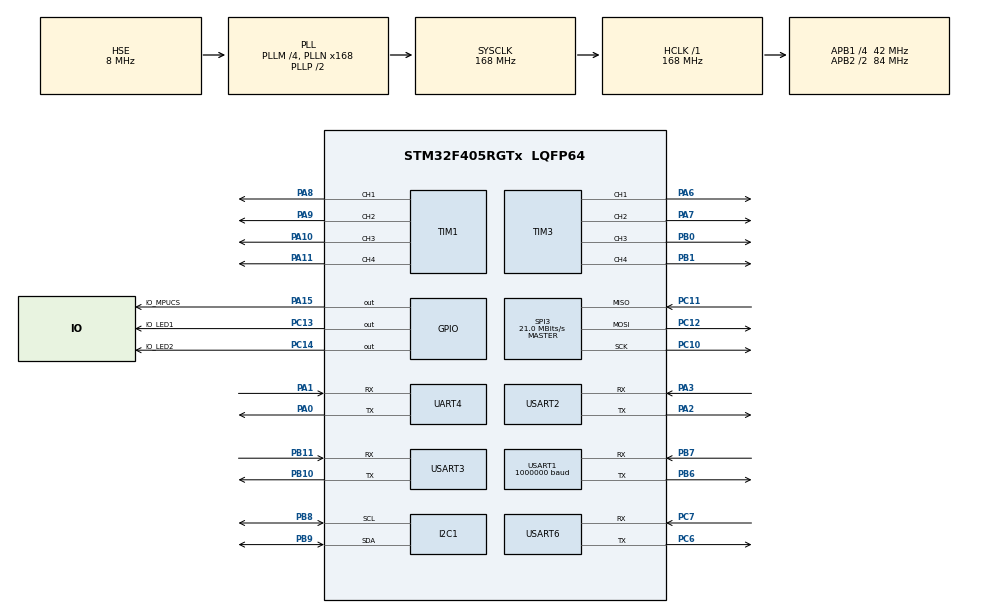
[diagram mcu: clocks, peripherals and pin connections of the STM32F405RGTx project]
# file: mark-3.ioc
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Dma.Request0=USART1_RX
Dma.Request1=USART1_TX
Dma.USART1_RX.0.Direction=DMA_PERIPH_TO_MEMORY
Dma.USART1_RX.0.FIFOMode=DMA_FIFOMODE_ENABLE
Dma.USART1_RX.0.FIFOThreshold=DMA_FIFO_THRESHOLD_FULL
Dma.USART1_RX.0.Instance=DMA2_Stream2
Dma.USART1_RX.0.MemBurst=DMA_MBURST_SINGLE
Dma.USART1_RX.0.MemDataAlignment=DMA_MDATAALIGN_BYTE
Dma.USART1_RX.0.MemInc=DMA_MINC_ENABLE
Dma.USART1_RX.0.Mode=DMA_CIRCULAR
Dma.USART1_RX.0.PeriphBurst=DMA_PBURST_SINGLE
Dma.USART1_RX.0.PeriphDataAlignment=DMA_PDATAALIGN_BYTE
Dma.USART1_RX.0.PeriphInc=DMA_PINC_DISABLE
Dma.USART1_RX.0.Priority=DMA_PRIORITY_LOW
Dma.USART1_TX.1.Direction=DMA_MEMORY_TO_PERIPH
Dma.USART1_TX.1.FIFOMode=DMA_FIFOMODE_ENABLE
Dma.USART1_TX.1.FIFOThreshold=DMA_FIFO_THRESHOLD_FULL
Dma.USART1_TX.1.Instance=DMA2_Stream7
Dma.USART1_TX.1.MemBurst=DMA_MBURST_SINGLE
Dma.USART1_TX.1.MemDataAlignment=DMA_MDATAALIGN_BYTE
Dma.USART1_TX.1.MemInc=DMA_MINC_ENABLE
Dma.USART1_TX.1.Mode=DMA_NORMAL
Dma.USART1_TX.1.PeriphBurst=DMA_PBURST_SINGLE
Dma.USART1_TX.1.PeriphDataAlignment=DMA_PDATAALIGN_BYTE
Dma.USART1_TX.1.PeriphInc=DMA_PINC_DISABLE
Dma.USART1_TX.1.Priority=DMA_PRIORITY_LOW
Mcu.Family=STM32F4
Mcu.Name=STM32F405RGTx
Mcu.Package=LQFP64
NVIC.DMA2_Stream2_IRQn=true\:0\:0\:false\:false\:true\:false\:true\:true
NVIC.DMA2_Stream7_IRQn=true\:0\:0\:false\:false\:true\:false\:true\:true
NVIC.I2C1_EV_IRQn=true\:0\:0\:false\:false\:true\:true\:true\:true
NVIC.PriorityGroup=NVIC_PRIORITYGROUP_4
NVIC.USART1_IRQn=true\:0\:0\:false\:false\:true\:true\:true\:true
PA0-WKUP.Mode=Asynchronous
PA0-WKUP.Signal=UART4_TX
PA1.Mode=Asynchronous
PA1.Signal=UART4_RX
PA10.Signal=S_TIM1_CH3
PA11.Signal=S_TIM1_CH4
PA13.Mode=Trace_Asynchronous_SW
PA13.Signal=SYS_JTMS-SWDIO
PA14.Mode=Trace_Asynchronous_SW
PA14.Signal=SYS_JTCK-SWCLK
PA15.GPIO_Label=IO_MPUCS
PA15.Signal=GPIO_Output
PA2.Mode=Asynchronous
PA2.Signal=USART2_TX
PA3.Mode=Asynchronous
PA3.Signal=USART2_RX
PA6.Signal=S_TIM3_CH1
PA7.Signal=S_TIM3_CH2
PA8.Signal=S_TIM1_CH1
PA9.Signal=S_TIM1_CH2
PB0.Signal=S_TIM3_CH3
PB1.Signal=S_TIM3_CH4
PB10.Mode=Asynchronous
PB10.Signal=USART3_TX
PB11.Mode=Asynchronous
PB11.Signal=USART3_RX
PB3.Mode=Trace_Asynchronous_SW
PB3.Signal=SYS_JTDO-SWO
PB6.Mode=Asynchronous
PB6.Signal=USART1_TX
PB7.Mode=Asynchronous
PB7.Signal=USART1_RX
PB8.Mode=I2C
PB8.Signal=I2C1_SCL
PB9.Mode=I2C
PB9.Signal=I2C1_SDA
PC10.Mode=Full_Duplex_Master
PC10.Signal=SPI3_SCK
PC11.Mode=Full_Duplex_Master
PC11.Signal=SPI3_MISO
PC12.Mode=Full_Duplex_Master
PC12.Signal=SPI3_MOSI
PC13-ANTI_TAMP.GPIO_Label=IO_LED1
PC13-ANTI_TAMP.Signal=GPIO_Output
PC14-OSC32_IN.GPIO_Label=IO_LED2
PC14-OSC32_IN.Signal=GPIO_Output
PC6.Mode=Asynchronous
PC6.Signal=USART6_TX
PC7.Mode=Asynchronous
PC7.Signal=USART6_RX
PH0-OSC_IN.Mode=HSE-External-Oscillator
PH0-OSC_IN.Signal=RCC_OSC_IN
PH1-OSC_OUT.Mode=HSE-External-Oscillator
PH1-OSC_OUT.Signal=RCC_OSC_OUT
ProjectManager.HeapSize=0x200
ProjectManager.StackSize=0x400
ProjectManager.TargetToolchain=STM32CubeIDE
RCC.48MHZClocksFreq_Value=84000000
RCC.AHBFreq_Value=168000000
RCC.APB1CLKDivider=RCC_HCLK_DIV4
RCC.APB1Freq_Value=42000000
RCC.APB1TimFreq_Value=84000000
RCC.APB2CLKDivider=RCC_HCLK_DIV2
RCC.APB2Freq_Value=84000000
RCC.APB2TimFreq_Value=168000000
RCC.CortexFreq_Value=168000000
RCC.HCLKFreq_Value=168000000
RCC.HSE_VALUE=8000000
RCC.HSI_VALUE=16000000
RCC.LSE_VALUE=32768
RCC.PLLM=4
RCC.PLLN=168
RCC.PLLSourceVirtual=RCC_PLLSOURCE_HSE
RCC.SYSCLKFreq_VALUE=168000000
RCC.SYSCLKSource=RCC_SYSCLKSOURCE_PLLCLK
RCC.VCOOutputFreq_Value=336000000
SH.S_TIM1_CH1.0=TIM1_CH1,PWM Generation1 CH1
SH.S_TIM1_CH2.0=TIM1_CH2,PWM Generation2 CH2
SH.S_TIM1_CH3.0=TIM1_CH3,PWM Generation3 CH3
SH.S_TIM1_CH4.0=TIM1_CH4,PWM Generation4 CH4
SH.S_TIM3_CH1.0=TIM3_CH1,PWM Generation1 CH1
SH.S_TIM3_CH2.0=TIM3_CH2,PWM Generation2 CH2
SH.S_TIM3_CH3.0=TIM3_CH3,PWM Generation3 CH3
SH.S_TIM3_CH4.0=TIM3_CH4,PWM Generation4 CH4
SPI3.CalculateBaudRate=21.0 MBits/s
SPI3.Direction=SPI_DIRECTION_2LINES
SPI3.Mode=SPI_MODE_MASTER
SPI3.VirtualType=VM_MASTER
TIM1.Channel-PWM\ Generation1\ CH1=TIM_CHANNEL_1
TIM1.Channel-PWM\ Generation2\ CH2=TIM_CHANNEL_2
TIM1.Channel-PWM\ Generation3\ CH3=TIM_CHANNEL_3
TIM1.Channel-PWM\ Generation4\ CH4=TIM_CHANNEL_4
TIM3.Channel-PWM\ Generation1\ CH1=TIM_CHANNEL_1
TIM3.Channel-PWM\ Generation2\ CH2=TIM_CHANNEL_2
TIM3.Channel-PWM\ Generation3\ CH3=TIM_CHANNEL_3
TIM3.Channel-PWM\ Generation4\ CH4=TIM_CHANNEL_4
UART4.VirtualMode=Asynchronous
USART1.BaudRate=1000000
USART1.VirtualMode=VM_ASYNC
USART2.VirtualMode=VM_ASYNC
USART3.VirtualMode=VM_ASYNC
USART6.VirtualMode=VM_ASYNC
VP_TIM1_VS_ClockSourceINT.Mode=Internal
VP_TIM3_VS_ClockSourceINT.Mode=Internal
board=custom

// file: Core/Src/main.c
/* USER CODE BEGIN Header */
/**
  ******************************************************************************
  * @file           : main.c
  * @brief          : Main program body
  ******************************************************************************
  * @attention
  *
  * Copyright (c) 2025 STMicroelectronics.
  * All rights reserved.
  *
  * This software is licensed under terms that can be found in the LICENSE file
  * in the root directory of this software component.
  * If no LICENSE file comes with this software, it is provided AS-IS.
  *
  ******************************************************************************
  */
/* USER CODE END Header */
#include "main.h"

/* USER CODE BEGIN PM */

#ifdef USE_NON_CUBEIDE_CODE
#include "mark3_main.hpp"
#endif /* USE_NON_CUBEIDE_CODE */

/* USER CODE END PM */

I2C_HandleTypeDef hi2c1;

SPI_HandleTypeDef hspi3;

TIM_HandleTypeDef htim1;
TIM_HandleTypeDef htim3;

UART_HandleTypeDef huart4;
UART_HandleTypeDef huart1;
UART_HandleTypeDef huart2;
UART_HandleTypeDef huart3;
UART_HandleTypeDef huart6;
DMA_HandleTypeDef hdma_usart1_rx;
DMA_HandleTypeDef hdma_usart1_tx;

void SystemClock_Config(void);
static void MX_GPIO_Init(void);
static void MX_DMA_Init(void);
static void MX_I2C1_Init(void);
static void MX_SPI3_Init(void);
static void MX_TIM1_Init(void);
static void MX_TIM3_Init(void);
static void MX_UART4_Init(void);
static void MX_USART1_UART_Init(void);
static void MX_USART2_UART_Init(void);
static void MX_USART3_UART_Init(void);
static void MX_USART6_UART_Init(void);

int main(void)
{

  /* MCU Configuration--------------------------------------------------------*/

  /* Reset of all peripherals, Initializes the Flash interface and the Systick. */
  HAL_Init();

  /* Configure the system clock */
  SystemClock_Config();

  /* Initialize all configured peripherals */
  MX_GPIO_Init();
  MX_DMA_Init();
  MX_I2C1_Init();
  MX_SPI3_Init();
  MX_TIM1_Init();
  MX_TIM3_Init();
  MX_UART4_Init();
  MX_USART1_UART_Init();
  MX_USART2_UART_Init();
  MX_USART3_UART_Init();
  MX_USART6_UART_Init();
  /* USER CODE BEGIN 2 */
#ifdef USE_NON_CUBEIDE_CODE
  mark3_main();
#endif /* USE_NON_CUBEIDE_CODE */

  /* USER CODE END 2 */

  /* Infinite loop */
  while (1)
  {

  }
}

void SystemClock_Config(void)
{
  RCC_OscInitTypeDef RCC_OscInitStruct = {0};
  RCC_ClkInitTypeDef RCC_ClkInitStruct = {0};

  /** Configure the main internal regulator output voltage
  */
  __HAL_RCC_PWR_CLK_ENABLE();
  __HAL_PWR_VOLTAGESCALING_CONFIG(PWR_REGULATOR_VOLTAGE_SCALE1);

  /** Initializes the RCC Oscillators according to the specified parameters
  * in the RCC_OscInitTypeDef structure.
  */
  RCC_OscInitStruct.OscillatorType = RCC_OSCILLATORTYPE_HSE;
  RCC_OscInitStruct.HSEState = RCC_HSE_ON;
  RCC_OscInitStruct.PLL.PLLState = RCC_PLL_ON;
  RCC_OscInitStruct.PLL.PLLSource = RCC_PLLSOURCE_HSE;
  RCC_OscInitStruct.PLL.PLLM = 4;
  RCC_OscInitStruct.PLL.PLLN = 168;
  RCC_OscInitStruct.PLL.PLLP = RCC_PLLP_DIV2;
  RCC_OscInitStruct.PLL.PLLQ = 4;
  if (HAL_RCC_OscConfig(&RCC_OscInitStruct) != HAL_OK)
  {
    Error_Handler();
  }

  /** Initializes the CPU, AHB and APB buses clocks
  */
  RCC_ClkInitStruct.ClockType = RCC_CLOCKTYPE_HCLK|RCC_CLOCKTYPE_SYSCLK
                              |RCC_CLOCKTYPE_PCLK1|RCC_CLOCKTYPE_PCLK2;
  RCC_ClkInitStruct.SYSCLKSource = RCC_SYSCLKSOURCE_PLLCLK;
  RCC_ClkInitStruct.AHBCLKDivider = RCC_SYSCLK_DIV1;
  RCC_ClkInitStruct.APB1CLKDivider = RCC_HCLK_DIV4;
  RCC_ClkInitStruct.APB2CLKDivider = RCC_HCLK_DIV2;

  if (HAL_RCC_ClockConfig(&RCC_ClkInitStruct, FLASH_LATENCY_5) != HAL_OK)
  {
    Error_Handler();
  }
}

static void MX_I2C1_Init(void)
{

  hi2c1.Instance = I2C1;
  hi2c1.Init.ClockSpeed = 100000;
  hi2c1.Init.DutyCycle = I2C_DUTYCYCLE_2;
  hi2c1.Init.OwnAddress1 = 0;
  hi2c1.Init.AddressingMode = I2C_ADDRESSINGMODE_7BIT;
  hi2c1.Init.DualAddressMode = I2C_DUALADDRESS_DISABLE;
  hi2c1.Init.OwnAddress2 = 0;
  hi2c1.Init.GeneralCallMode = I2C_GENERALCALL_DISABLE;
  hi2c1.Init.NoStretchMode = I2C_NOSTRETCH_DISABLE;
  if (HAL_I2C_Init(&hi2c1) != HAL_OK)
  {
    Error_Handler();
  }

}

static void MX_SPI3_Init(void)
{

  /* SPI3 parameter configuration*/
  hspi3.Instance = SPI3;
  hspi3.Init.Mode = SPI_MODE_MASTER;
  hspi3.Init.Direction = SPI_DIRECTION_2LINES;
  hspi3.Init.DataSize = SPI_DATASIZE_8BIT;
  hspi3.Init.CLKPolarity = SPI_POLARITY_LOW;
  hspi3.Init.CLKPhase = SPI_PHASE_1EDGE;
  hspi3.Init.NSS = SPI_NSS_SOFT;
  hspi3.Init.BaudRatePrescaler = SPI_BAUDRATEPRESCALER_2;
  hspi3.Init.FirstBit = SPI_FIRSTBIT_MSB;
  hspi3.Init.TIMode = SPI_TIMODE_DISABLE;
  hspi3.Init.CRCCalculation = SPI_CRCCALCULATION_DISABLE;
  hspi3.Init.CRCPolynomial = 10;
  if (HAL_SPI_Init(&hspi3) != HAL_OK)
  {
    Error_Handler();
  }

}

static void MX_TIM1_Init(void)
{

  TIM_ClockConfigTypeDef sClockSourceConfig = {0};
  TIM_MasterConfigTypeDef sMasterConfig = {0};
  TIM_OC_InitTypeDef sConfigOC = {0};
  TIM_BreakDeadTimeConfigTypeDef sBreakDeadTimeConfig = {0};

  htim1.Instance = TIM1;
  htim1.Init.Prescaler = 0;
  htim1.Init.CounterMode = TIM_COUNTERMODE_UP;
  htim1.Init.Period = 65535;
  htim1.Init.ClockDivision = TIM_CLOCKDIVISION_DIV1;
  htim1.Init.RepetitionCounter = 0;
  htim1.Init.AutoReloadPreload = TIM_AUTORELOAD_PRELOAD_DISABLE;
  if (HAL_TIM_Base_Init(&htim1) != HAL_OK)
  {
    Error_Handler();
  }
  sClockSourceConfig.ClockSource = TIM_CLOCKSOURCE_INTERNAL;
  if (HAL_TIM_ConfigClockSource(&htim1, &sClockSourceConfig) != HAL_OK)
  {
    Error_Handler();
  }
  if (HAL_TIM_PWM_Init(&htim1) != HAL_OK)
  {
    Error_Handler();
  }
  sMasterConfig.MasterOutputTrigger = TIM_TRGO_RESET;
  sMasterConfig.MasterSlaveMode = TIM_MASTERSLAVEMODE_DISABLE;
  if (HAL_TIMEx_MasterConfigSynchronization(&htim1, &sMasterConfig) != HAL_OK)
  {
    Error_Handler();
  }
  sConfigOC.OCMode = TIM_OCMODE_PWM1;
  sConfigOC.Pulse = 0;
  sConfigOC.OCPolarity = TIM_OCPOLARITY_HIGH;
  sConfigOC.OCNPolarity = TIM_OCNPOLARITY_HIGH;
  sConfigOC.OCFastMode = TIM_OCFAST_DISABLE;
  sConfigOC.OCIdleState = TIM_OCIDLESTATE_RESET;
  sConfigOC.OCNIdleState = TIM_OCNIDLESTATE_RESET;
  if (HAL_TIM_PWM_ConfigChannel(&htim1, &sConfigOC, TIM_CHANNEL_1) != HAL_OK)
  {
    Error_Handler();
  }
  if (HAL_TIM_PWM_ConfigChannel(&htim1, &sConfigOC, TIM_CHANNEL_2) != HAL_OK)
  {
    Error_Handler();
  }
  if (HAL_TIM_PWM_ConfigChannel(&htim1, &sConfigOC, TIM_CHANNEL_3) != HAL_OK)
  {
    Error_Handler();
  }
  if (HAL_TIM_PWM_ConfigChannel(&htim1, &sConfigOC, TIM_CHANNEL_4) != HAL_OK)
  {
    Error_Handler();
  }
  sBreakDeadTimeConfig.OffStateRunMode = TIM_OSSR_DISABLE;
  sBreakDeadTimeConfig.OffStateIDLEMode = TIM_OSSI_DISABLE;
  sBreakDeadTimeConfig.LockLevel = TIM_LOCKLEVEL_OFF;
  sBreakDeadTimeConfig.DeadTime = 0;
  sBreakDeadTimeConfig.BreakState = TIM_BREAK_DISABLE;
  sBreakDeadTimeConfig.BreakPolarity = TIM_BREAKPOLARITY_HIGH;
  sBreakDeadTimeConfig.AutomaticOutput = TIM_AUTOMATICOUTPUT_DISABLE;
  if (HAL_TIMEx_ConfigBreakDeadTime(&htim1, &sBreakDeadTimeConfig) != HAL_OK)
  {
    Error_Handler();
  }
  HAL_TIM_MspPostInit(&htim1);

}

static void MX_TIM3_Init(void)
{

  TIM_ClockConfigTypeDef sClockSourceConfig = {0};
  TIM_MasterConfigTypeDef sMasterConfig = {0};
  TIM_OC_InitTypeDef sConfigOC = {0};

  htim3.Instance = TIM3;
  htim3.Init.Prescaler = 0;
  htim3.Init.CounterMode = TIM_COUNTERMODE_UP;
  htim3.Init.Period = 65535;
  htim3.Init.ClockDivision = TIM_CLOCKDIVISION_DIV1;
  htim3.Init.AutoReloadPreload = TIM_AUTORELOAD_PRELOAD_DISABLE;
  if (HAL_TIM_Base_Init(&htim3) != HAL_OK)
  {
    Error_Handler();
  }
  sClockSourceConfig.ClockSource = TIM_CLOCKSOURCE_INTERNAL;
  if (HAL_TIM_ConfigClockSource(&htim3, &sClockSourceConfig) != HAL_OK)
  {
    Error_Handler();
  }
  if (HAL_TIM_PWM_Init(&htim3) != HAL_OK)
  {
    Error_Handler();
  }
  sMasterConfig.MasterOutputTrigger = TIM_TRGO_RESET;
  sMasterConfig.MasterSlaveMode = TIM_MASTERSLAVEMODE_DISABLE;
  if (HAL_TIMEx_MasterConfigSynchronization(&htim3, &sMasterConfig) != HAL_OK)
  {
    Error_Handler();
  }
  sConfigOC.OCMode = TIM_OCMODE_PWM1;
  sConfigOC.Pulse = 0;
  sConfigOC.OCPolarity = TIM_OCPOLARITY_HIGH;
  sConfigOC.OCFastMode = TIM_OCFAST_DISABLE;
  if (HAL_TIM_PWM_ConfigChannel(&htim3, &sConfigOC, TIM_CHANNEL_1) != HAL_OK)
  {
    Error_Handler();
  }
  if (HAL_TIM_PWM_ConfigChannel(&htim3, &sConfigOC, TIM_CHANNEL_2) != HAL_OK)
  {
    Error_Handler();
  }
  if (HAL_TIM_PWM_ConfigChannel(&htim3, &sConfigOC, TIM_CHANNEL_3) != HAL_OK)
  {
    Error_Handler();
  }
  if (HAL_TIM_PWM_ConfigChannel(&htim3, &sConfigOC, TIM_CHANNEL_4) != HAL_OK)
  {
    Error_Handler();
  }
  HAL_TIM_MspPostInit(&htim3);

}

static void MX_UART4_Init(void)
{

  huart4.Instance = UART4;
  huart4.Init.BaudRate = 115200;
  huart4.Init.WordLength = UART_WORDLENGTH_8B;
  huart4.Init.StopBits = UART_STOPBITS_1;
  huart4.Init.Parity = UART_PARITY_NONE;
  huart4.Init.Mode = UART_MODE_TX_RX;
  huart4.Init.HwFlowCtl = UART_HWCONTROL_NONE;
  huart4.Init.OverSampling = UART_OVERSAMPLING_16;
  if (HAL_UART_Init(&huart4) != HAL_OK)
  {
    Error_Handler();
  }

}

static void MX_USART1_UART_Init(void)
{

  huart1.Instance = USART1;
  huart1.Init.BaudRate = 1000000;
  huart1.Init.WordLength = UART_WORDLENGTH_8B;
  huart1.Init.StopBits = UART_STOPBITS_1;
  huart1.Init.Parity = UART_PARITY_NONE;
  huart1.Init.Mode = UART_MODE_TX_RX;
  huart1.Init.HwFlowCtl = UART_HWCONTROL_NONE;
  huart1.Init.OverSampling = UART_OVERSAMPLING_16;
  if (HAL_UART_Init(&huart1) != HAL_OK)
  {
    Error_Handler();
  }

}

static void MX_USART2_UART_Init(void)
{

  huart2.Instance = USART2;
  huart2.Init.BaudRate = 115200;
  huart2.Init.WordLength = UART_WORDLENGTH_8B;
  huart2.Init.StopBits = UART_STOPBITS_1;
  huart2.Init.Parity = UART_PARITY_NONE;
  huart2.Init.Mode = UART_MODE_TX_RX;
  huart2.Init.HwFlowCtl = UART_HWCONTROL_NONE;
  huart2.Init.OverSampling = UART_OVERSAMPLING_16;
  if (HAL_UART_Init(&huart2) != HAL_OK)
  {
    Error_Handler();
  }

}

static void MX_USART3_UART_Init(void)
{

  huart3.Instance = USART3;
  huart3.Init.BaudRate = 115200;
  huart3.Init.WordLength = UART_WORDLENGTH_8B;
  huart3.Init.StopBits = UART_STOPBITS_1;
  huart3.Init.Parity = UART_PARITY_NONE;
  huart3.Init.Mode = UART_MODE_TX_RX;
  huart3.Init.HwFlowCtl = UART_HWCONTROL_NONE;
  huart3.Init.OverSampling = UART_OVERSAMPLING_16;
  if (HAL_UART_Init(&huart3) != HAL_OK)
  {
    Error_Handler();
  }

}

static void MX_USART6_UART_Init(void)
{

  huart6.Instance = USART6;
  huart6.Init.BaudRate = 115200;
  huart6.Init.WordLength = UART_WORDLENGTH_8B;
  huart6.Init.StopBits = UART_STOPBITS_1;
  huart6.Init.Parity = UART_PARITY_NONE;
  huart6.Init.Mode = UART_MODE_TX_RX;
  huart6.Init.HwFlowCtl = UART_HWCONTROL_NONE;
  huart6.Init.OverSampling = UART_OVERSAMPLING_16;
  if (HAL_UART_Init(&huart6) != HAL_OK)
  {
    Error_Handler();
  }

}

static void MX_DMA_Init(void)
{

  /* DMA controller clock enable */
  __HAL_RCC_DMA2_CLK_ENABLE();

  /* DMA interrupt init */
  /* DMA2_Stream2_IRQn interrupt configuration */
  HAL_NVIC_SetPriority(DMA2_Stream2_IRQn, 0, 0);
  HAL_NVIC_EnableIRQ(DMA2_Stream2_IRQn);
  /* DMA2_Stream7_IRQn interrupt configuration */
  HAL_NVIC_SetPriority(DMA2_Stream7_IRQn, 0, 0);
  HAL_NVIC_EnableIRQ(DMA2_Stream7_IRQn);

}

static void MX_GPIO_Init(void)
{
  GPIO_InitTypeDef GPIO_InitStruct = {0};

  /* GPIO Ports Clock Enable */
  __HAL_RCC_GPIOC_CLK_ENABLE();
  __HAL_RCC_GPIOH_CLK_ENABLE();
  __HAL_RCC_GPIOA_CLK_ENABLE();
  __HAL_RCC_GPIOB_CLK_ENABLE();

  /*Configure GPIO pin Output Level */
  HAL_GPIO_WritePin(GPIOC, IO_LED1_Pin|IO_LED2_Pin, GPIO_PIN_RESET);

  /*Configure GPIO pin Output Level */
  HAL_GPIO_WritePin(IO_MPUCS_GPIO_Port, IO_MPUCS_Pin, GPIO_PIN_RESET);

  /*Configure GPIO pins : IO_LED1_Pin IO_LED2_Pin */
  GPIO_InitStruct.Pin = IO_LED1_Pin|IO_LED2_Pin;
  GPIO_InitStruct.Mode = GPIO_MODE_OUTPUT_PP;
  GPIO_InitStruct.Pull = GPIO_NOPULL;
  GPIO_InitStruct.Speed = GPIO_SPEED_FREQ_LOW;
  HAL_GPIO_Init(GPIOC, &GPIO_InitStruct);

  /*Configure GPIO pin : IO_MPUCS_Pin */
  GPIO_InitStruct.Pin = IO_MPUCS_Pin;
  GPIO_InitStruct.Mode = GPIO_MODE_OUTPUT_PP;
  GPIO_InitStruct.Pull = GPIO_NOPULL;
  GPIO_InitStruct.Speed = GPIO_SPEED_FREQ_LOW;
  HAL_GPIO_Init(IO_MPUCS_GPIO_Port, &GPIO_InitStruct);

}

void Error_Handler(void)
{
  __disable_irq();
  while (1)
  {
  }
}
